# N32G41x register map
Vendor: Nsingtech Ltd.; File version: 1.0
CPU: CM4 r0p1, little endian, no MPU, no FPU, 4 interrupt priority bits
Registers are 32-bit, read-write, reset 0x0 unless marked. A register's access mark holds for its fields unless they carry their own. Offsets are from the block's base; [hi:lo] are bit positions; {n}, {i} and the like mark numbered series.

## GTIM3 — General-purpose Timer 3
Base 0x40000800
Same registers: GTIM4 0x40000C00
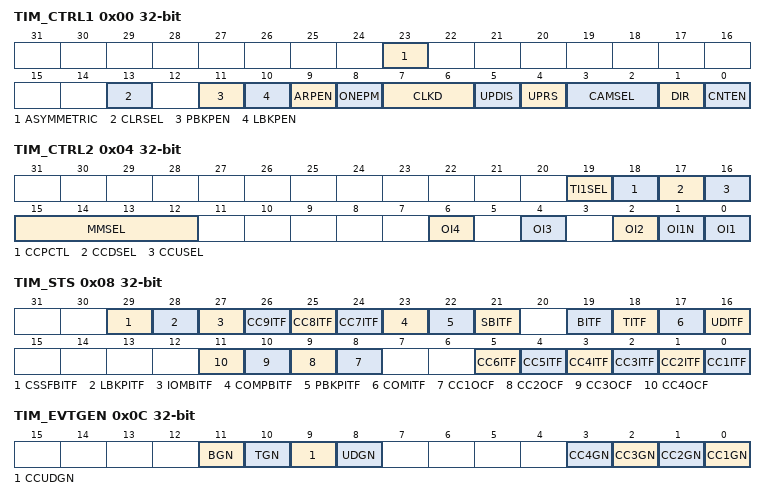
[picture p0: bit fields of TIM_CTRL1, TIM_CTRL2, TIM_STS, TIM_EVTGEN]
0x00 TIM_CTRL1 — TIM Control Register 1
  [23] ASYMMETRIC — Asymmetric mode enable
  [13] CLRSEL — OcxRef clear selection
  [11] PBKPEN — PVD as BRK enable
  [10] LBKPEN — LockUp as BRK enable
  [9] ARPEN — Auto-reload preload enable
  [8] ONEPM — One pulse mode
  [7:6] CLKD — Clock division
  [5] UPDIS — Update disable
  [4] UPRS — Update request source
  [3:2] CAMSEL — Center-aligned mode selection
  [1] DIR — Direction
  [0] CNTEN — Counter enable
0x04 TIM_CTRL2 — TIM Control Register 2
  [19] TI1SEL — TI1 selection
  [18] CCPCTL — Capture/compare preloaded control
  [17] CCDSEL — Capture/compare DMA selection
  [16] CCUSEL — Capture/compare control update selection
  [15:12] MMSEL — Master mode selection
  [2n-2] OI{n} (n=1..4) — Output idle state {n}
  [1] OI1N — Output idle state 1N
0x08 TIM_STS — TIM Status Register
  [29] CSSFBITF — CSSF break interrupt flag
  [28] LBKPITF — Lockup break interrupt flag
  [27] IOMBITF — IOM break interrupt flag
  [26] CC9ITF — Capture/Compare 9 interrupt flag
  [25] CC8ITF — Capture/Compare 8 interrupt flag
  [24] CC7ITF — Capture/Compare 7 interrupt flag
  [23] COMPBITF — COMP break interrupt flag
  [22] PBKPITF — PVD break interrupt flag
  [21] SBITF — System break interrupt flag
  [19] BITF — Break1 interrupt flag
  [18] TITF — Trigger interrupt flag
  [17] COMITF — COM interrupt flag
  [16] UDITF — Update interrupt flag
  [n+7] CC{n}OCF (n=1..4) — Capture/Compare {n} overcapture flag
  [n-1] CC{n}ITF (n=1..6) — Capture/Compare {n} interrupt flag
0x0C TIM_EVTGEN wo — TIM Event Generation Register
  [11] BGN — Break1 generation
  [10] TGN — Trigger generation
  [9] CCUDGN — Capture/Compare control update generation
  [8] UDGN — Update generation
  [n-1] CC{n}GN (n=1..4) — Capture/Compare {n} generation
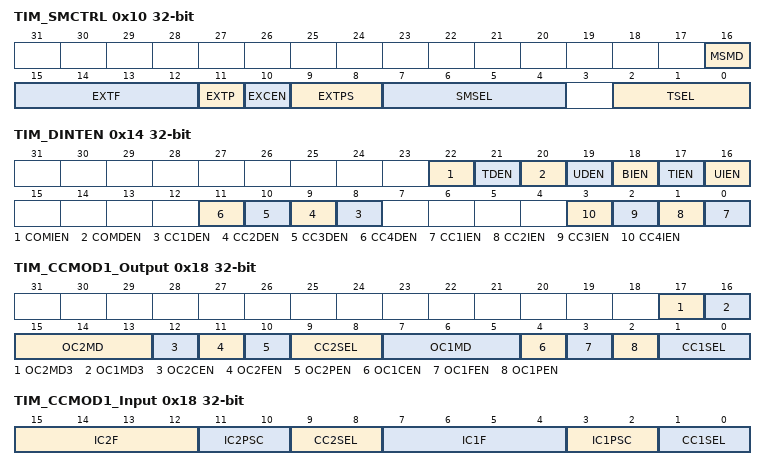
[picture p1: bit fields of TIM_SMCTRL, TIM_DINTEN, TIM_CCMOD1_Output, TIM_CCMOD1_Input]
0x10 TIM_SMCTRL — TIM Slave Mode Control Register
  [16] MSMD — Master/slave mode
  [15:12] EXTF — External trigger filter
  [11] EXTP — External trigger polarity
  [10] EXCEN — External clock enable
  [9:8] EXTPS — External trigger prescaler
  [7:4] SMSEL — Slave mode selection
  [2:0] TSEL — Trigger selection
0x14 TIM_DINTEN — TIM DMA/Interrupt Enable Register
  [22] COMIEN — COM interrupt enable
  [21] TDEN — Trigger DMA request enable
  [20] COMDEN — COM DMA request enable
  [19] UDEN — Update DMA request enable
  [18] BIEN — Break interrupt enable
  [17] TIEN — Trigger interrupt enable
  [16] UIEN — Update interrupt enable
  [n+7] CC{n}DEN (n=1..4) — Capture/Compare {n} DMA request enable
  [n-1] CC{n}IEN (n=1..4) — Capture/Compare {n} interrupt enable
0x18 TIM_CCMOD1_Output — TIM Capture/Compare Mode Register 1 Output
  [17] OC2MD3 — Output compare 2 mode bit3
  [16] OC1MD3 — Output compare 1 mode bit3
  [15:13] OC2MD — Output compare 2 mode
  [12] OC2CEN — OC2 clear enable
  [11] OC2FEN — OC2 fast enable
  [10] OC2PEN — OC2 preload enable
  [9:8] CC2SEL — Capture/Compare 2 selection
  [7:5] OC1MD — Output compare 1 mode
  [4] OC1CEN — OC1 clear enable
  [3] OC1FEN — OC1 fast enable
  [2] OC1PEN — OC1 preload enable
  [1:0] CC1SEL — Capture/Compare 1 selection
0x18 TIM_CCMOD1_Input (alternate view of TIM_CCMOD1_Output) — TIM Capture/Compare Mode Register 1 Input
  [15:12] IC2F — Input capture 2 filter
  [11:10] IC2PSC — Input capture 2 prescaler
  [9:8] CC2SEL — Capture/Compare 2 selection
  [7:4] IC1F — Input capture 1 filter
  [3:2] IC1PSC — Input capture 1 prescaler
  [1:0] CC1SEL — Capture/Compare 1 selection
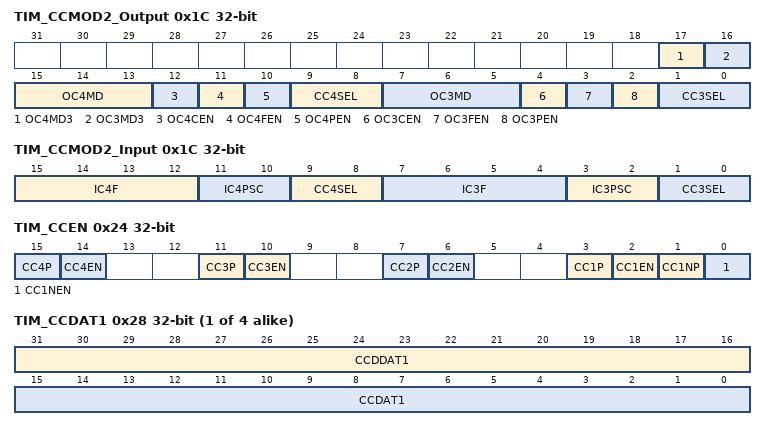
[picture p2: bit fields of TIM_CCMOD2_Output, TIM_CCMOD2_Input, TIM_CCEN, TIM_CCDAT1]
0x1C TIM_CCMOD2_Output — TIM Capture/Compare Mode Register 2 Output
  [17] OC4MD3 — Output compare 4 mode bit3
  [16] OC3MD3 — Output compare 3 mode bit3
  [15:13] OC4MD — Output compare 4 mode
  [12] OC4CEN — OC4 clear enable
  [11] OC4FEN — OC4 fast enable
  [10] OC4PEN — OC4 preload enable
  [9:8] CC4SEL — Capture/Compare 4 selection
  [7:5] OC3MD — Output compare 3 mode
  [4] OC3CEN — OC3 clear enable
  [3] OC3FEN — OC3 fast enable
  [2] OC3PEN — OC3 preload enable
  [1:0] CC3SEL — Capture/Compare 3 selection
0x1C TIM_CCMOD2_Input (alternate view of TIM_CCMOD2_Output) — TIM Capture/Compare Mode Register 2 Input
  [15:12] IC4F — Input capture 4 filter
  [11:10] IC4PSC — Input capture 4 prescaler
  [9:8] CC4SEL — Capture/Compare 4 selection
  [7:4] IC3F — Input capture 3 filter
  [3:2] IC3PSC — Input capture 3 prescaler
  [1:0] CC3SEL — Capture/Compare 3 selection
0x24 TIM_CCEN — TIM Capture/Compare Enable Register
  [4n-1] CC{n}P (n=1..4) — Capture/Compare {n} output polarity
  [4n-2] CC{n}EN (n=1..4) — Capture/Compare {n} output enable
  [1] CC1NP — Capture/Compare 1 complementary output polarity
  [0] CC1NEN — Capture/Compare 1 complementary output enable
{0x24+4i} TIM_CCDAT{i} (i=1..4) — TIM Capture/Compare Register {i}
  [31:16] CCDDAT{i} — Capture/Compare down-counting value
  [15:0] CCDAT{i} — Capture/Compare value
0x40 TIM_PSC — TIM Prescaler Register
  [15:0] PSC — Prescaler value
0x44 TIM_AR reset 0xFFFF — TIM Auto-Reload Register
  [15:0] AR — Auto-reload value
0x48 TIM_CNT — TIM Counter Register
  [15:0] CNT — Counter value
0x4C TIM_REPCNT — TIM Repetition Counter Register
  [7:0] REPCNT — Repetition counter value
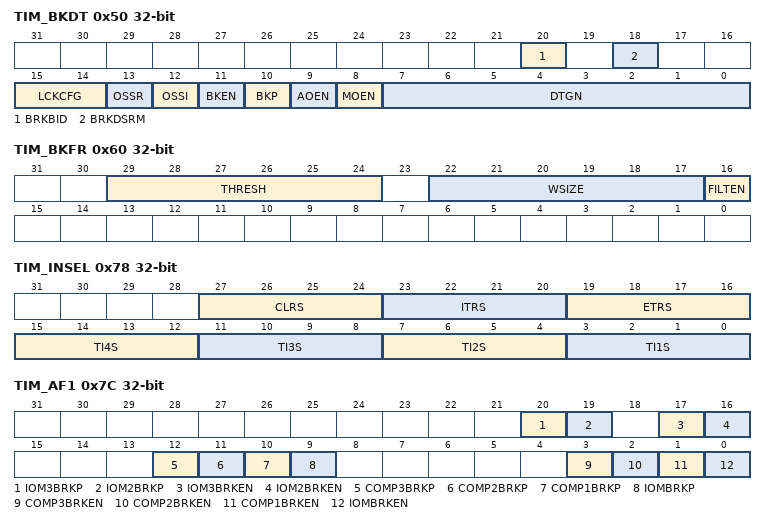
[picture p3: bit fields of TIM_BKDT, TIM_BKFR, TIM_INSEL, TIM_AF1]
0x50 TIM_BKDT — TIM Break and Dead-Time Register
  [20] BRKBID — Break1 bidirectional enable
  [18] BRKDSRM — Break1 disarm
  [15:14] LCKCFG — Lock configuration
  [13] OSSR — Off-state selection for Run mode
  [12] OSSI — Off-state selection for Idle mode
  [11] BKEN — Break1 enable
  [10] BKP — Break1 polarity
  [9] AOEN — Automatic output enable
  [8] MOEN — Main output enable
  [7:0] DTGN — Dead-time generator setup
0x60 TIM_BKFR — TIM Break Filter Register
  [29:24] THRESH — Threshold
  [22:17] WSIZE — Window size
  [16] FILTEN — Filter enable
0x78 TIM_INSEL — TIM Input Selection Register
  [27:24] CLRS — Select tim_ocref_clr input
  [23:20] ITRS — Select tim_itr input
  [19:16] ETRS — Select tim_etr input
  [4n-1:4n-4] TI{n}S (n=1..4) — Select tim_ti{n} input
0x7C TIM_AF1 — TIM Alternate Function Register 1
  [20] IOM3BRKP — BKIN IO3 brake polarity
  [19] IOM2BRKP — BKIN IO2 brake polarity
  [17] IOM3BRKEN — BKIN IO3 brake enable
  [16] IOM2BRKEN — BKIN IO2 brake enable
  [12] COMP3BRKP — COMP3 brake polarity
  [11] COMP2BRKP — COMP2 brake polarity
  [10] COMP1BRKP — COMP1 brake polarity
  [9] IOMBRKP — BKIN brake polarity
  [3] COMP3BRKEN — COMP3 brake enable
  [2] COMP2BRKEN — COMP2 brake enable
  [1] COMP1BRKEN — COMP1 brake enable
  [0] IOMBRKEN — BKIN brake enable
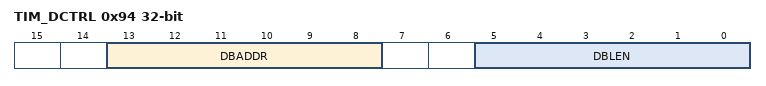
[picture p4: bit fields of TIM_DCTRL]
0x94 TIM_DCTRL — TIM DMA Control Register
  [13:8] DBADDR — DMA base address
  [5:0] DBLEN — DMA burst length
0x98 TIM_DADDR — TIM DMA Address Register
  [31:0] BURST — DMA access buffer

## ATIM1 — Advanced Timer 1
Base 0x40012C00
Same registers: ATIM2 0x40013400
Registers as GTIM3; these are added or differ:
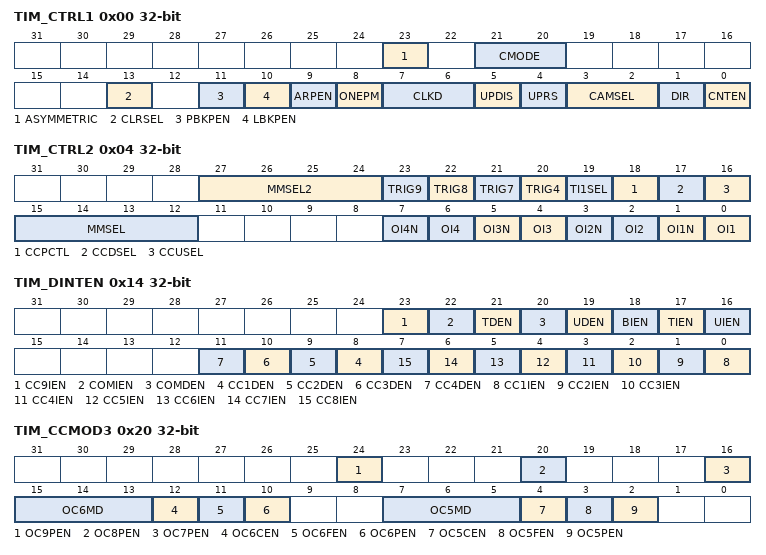
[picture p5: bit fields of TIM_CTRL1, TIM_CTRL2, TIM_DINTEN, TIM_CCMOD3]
0x00 TIM_CTRL1 — TIM Control Register 1
  [23] ASYMMETRIC — Asymmetric mode enable
  [21:20] CMODE — Center-aligned mode
  [13] CLRSEL — OCxRef clear selection
  [11] PBKPEN wo — PVD as BRK enable
  [10] LBKPEN wo — LockUp as BRK enable
  [9] ARPEN — Auto-reload preload enable
  [8] ONEPM — One pulse mode
  [7:6] CLKD — Clock division
  [5] UPDIS — Update disable
  [4] UPRS — Update request source
  [3:2] CAMSEL — Center-aligned mode selection
  [1] DIR — Direction
  [0] CNTEN — Counter enable
0x04 TIM_CTRL2 — TIM Control Register 2
  [27:24] MMSEL2 — Master mode select 2
  [23] TRIG9 — Channel 9 ADC trigger
  [22] TRIG8 — Channel 8 ADC trigger
  [21] TRIG7 — Channel 7 ADC trigger
  [20] TRIG4 — Channel 4 ADC trigger
  [19] TI1SEL — TI1 selection
  [18] CCPCTL — Capture/compare preloaded control
  [17] CCDSEL — Capture/compare DMA selection
  [16] CCUSEL — Capture/compare control update selection
  [15:12] MMSEL — Master mode selection
  [2n-1] OI{n}N (n=1..4) — Output idle state {n}N
  [2n-2] OI{n} (n=1..4) — Output idle state {n}
0x14 TIM_DINTEN — TIM DMA/Interrupt Enable Register
  [23] CC9IEN — Capture/Compare 9 interrupt enable
  [22] COMIEN — COM interrupt enable
  [21] TDEN — Trigger DMA request enable
  [20] COMDEN — COM DMA request enable
  [19] UDEN — Update DMA request enable
  [18] BIEN — Break interrupt enable
  [17] TIEN — Trigger interrupt enable
  [16] UIEN — Update interrupt enable
  [n+7] CC{n}DEN (n=1..4) — Capture/Compare {n} DMA request enable
  [n-1] CC{n}IEN (n=1..8) — Capture/Compare {n} interrupt enable
0x20 TIM_CCMOD3 — TIM Capture/Compare Mode Register 3
  [24] OC9PEN — Output compare 9 preload enable
  [20] OC8PEN — Output compare 8 preload enable
  [16] OC7PEN — Output compare 7 preload enable
  [15:13] OC6MD — Output compare 6 mode
  [12] OC6CEN — OC6 clear enable
  [11] OC6FEN — OC6 fast enable
  [10] OC6PEN — OC6 preload enable
  [7:5] OC5MD — Output compare 5 mode
  [4] OC5CEN — OC5 clear enable
  [3] OC5FEN — OC5 fast enable
  [2] OC5PEN — OC5 preload enable
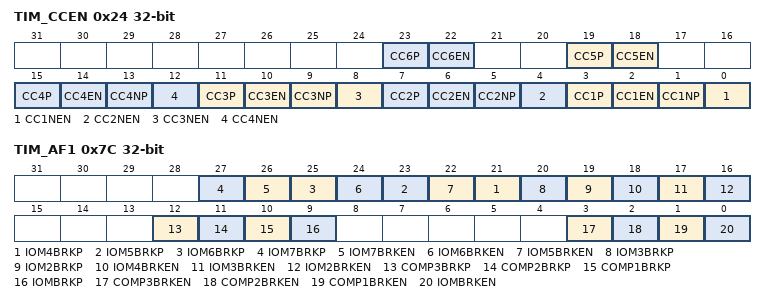
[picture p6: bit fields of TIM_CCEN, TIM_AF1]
0x24 TIM_CCEN — TIM Capture/Compare Enable Register
  [4n-1] CC{n}P (n=1..6) — Capture/Compare {n} output polarity
  [4n-2] CC{n}EN (n=1..6) — Capture/Compare {n} output enable
  [4n-3] CC{n}NP (n=1..4) — Capture/Compare {n} complementary output polarity
  [4n-4] CC{n}NEN (n=1..4) — Capture/Compare {n} complementary output enable
0x38 TIM_CCDAT5 — TIM Capture/Compare Register 5
  [15:0] CCDAT5 — Capture/Compare value
0x3C TIM_CCDAT6 — TIM Capture/Compare Register 6
  [15:0] CCDAT6 — Capture/Compare value
{0x38+4i} TIM_CCDAT{i} (i=7..9) — TIM Capture/Compare Register {i}
  [15:0] CCDAT{i} — Capture/Compare value
0x7C TIM_AF1 — TIM Alternate Function Register 1
  [2n+13] IOM{n}BRKP (n=4..7) — BKIN IO{n} brake polarity
  [26] IOM7BRKEN — BKIN IO7 brake enable
  [24] IOM6BRKEN — BKIN IO6 brake enable
  [22] IOM5BRKEN — BKIN IO5 brake enable
  [20] IOM3BRKP — BKIN IO3 brake polarity
  [19] IOM2BRKP — BKIN IO2 brake polarity
  [18] IOM4BRKEN — BKIN IO4 brake enable
  [17] IOM3BRKEN — BKIN IO3 brake enable
  [16] IOM2BRKEN — BKIN IO2 brake enable
  [12] COMP3BRKP — COMP3 brake polarity
  [11] COMP2BRKP — COMP2 brake polarity
  [10] COMP1BRKP — COMP1 brake polarity
  [9] IOMBRKP — BKIN brake polarity
  [3] COMP3BRKEN — COMP3 brake enable
  [2] COMP2BRKEN — COMP2 brake enable
  [1] COMP1BRKEN — COMP1 brake enable
  [0] IOMBRKEN — BKIN brake enable
